# PIC32CZ8110CA90208 register map
Vendor: Microchip Technology; Series: PIC32CZCA90; File version: 0
CPU: CM7 r1p1, little endian, MPU, FPU, double-precision FPU, I-cache, D-cache, ITCM, DTCM, 3 interrupt priority bits, 222 interrupts
Registers are 32-bit, read-write, reset 0x0 unless marked. A register's access mark holds for its fields unless they carry their own. Offsets are from the block's base; [hi:lo] are bit positions; {n}, {i} and the like mark numbered series; 'fields as' and 'values as' point back to an identical list.

## PAC — Peripheral Access Controller
Base 0x44810000
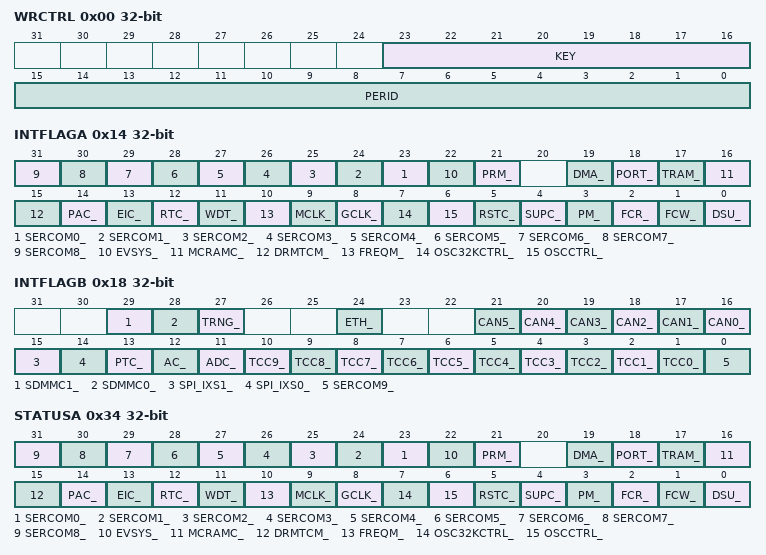
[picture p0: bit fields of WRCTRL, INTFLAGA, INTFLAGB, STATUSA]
0x00 WRCTRL — Write control
  [23:16] KEY — Peripheral access control key
    0=OFF (No action); 1=CLR (Clear protection); 2=SET (Set protection); 3=SETLCK (Set and lock protection)
  [15:0] PERID — Peripheral identifier
0x04 EVCTRL 8-bit — Event control
  [0] ERREO — Peripheral acess error event output
0x08 INTENCLR 8-bit write-1-clears — Interrupt enable clear
  [0] ERR — Peripheral access error interrupt disable
0x09 INTENSET 8-bit write-1-sets — Interrupt enable set
  [0] ERR — Peripheral access error interrupt enable
0x10 INTFLAGAHB write-1-clears — Bridge interrupt flag status
0x14 INTFLAGA write-1-clears — Peripheral interrupt flag status - Bridge A
  [n+23] SERCOM{n}_ (n=0..8), [22] EVSYS_, [21] PRM_, [19] DMA_, [18] PORT_, [17] TRAM_, [16] MCRAMC_, [15] DRMTCM_, [14] PAC_, [13] EIC_, [12] RTC_, [11] WDT_, [10] FREQM_, [9] MCLK_, [8] GCLK_, [7] OSC32KCTRL_, [6] OSCCTRL_, [5] RSTC_, [4] SUPC_, [3] PM_, [2] FCR_, [1] FCW_, [0] DSU_
0x18 INTFLAGB write-1-clears — Peripheral interrupt flag status - Bridge B
  [29] SDMMC1_, [28] SDMMC0_, [27] TRNG_, [24] ETH_, [n+16] CAN{n}_ (n=0..5), [15] SPI_IXS1_, [14] SPI_IXS0_, [13] PTC_, [12] AC_, [11] ADC_, [n+1] TCC{n}_ (n=0..9), [0] SERCOM9_
0x1C INTFLAGC write-1-clears — Peripheral interrupt flag status - Bridge C
  [2] MLB_
0x34 STATUSA ro — Peripheral write protection status - Bridge A
  [n+23] SERCOM{n}_ (n=0..8) — SERCOM{n} APB Protect Enable
  [22] EVSYS_ — EVSYS APB Protect Enable
  [21] PRM_ — PRM APB Protect Enable
  [19] DMA_ — DMA APB Protect Enable
  [18] PORT_ — PORT APB Protect Enable
  [17] TRAM_ — TRAM APB Protect Enable
  [16] MCRAMC_ — MCRAMC APB Protect Enable
  [15] DRMTCM_ — DRMTCM APB Protect Enable
  [14] PAC_ — PAC APB Protect Enable
  [13] EIC_ — EIC APB Protect Enable
  [12] RTC_ — RTC APB Protect Enable
  [11] WDT_ — WDT APB Protect Enable
  [10] FREQM_ — FREQM APB Protect Enable
  [9] MCLK_ — MCLK APB Protect Enable
  [8] GCLK_ — GCLK APB Protect Enable
  [7] OSC32KCTRL_ — OSC32KCTRL APB Protect Enable
  [6] OSCCTRL_ — OSCCTRL APB Protect Enable
  [5] RSTC_ — RSTC APB Protect Enable
  [4] SUPC_ — SUPC APB Protect Enable
  [3] PM_ — PM APB Protect Enable
  [2] FCR_ — FCR APB Protect Enable
  [1] FCW_ — FCW APB Protect Enable
  [0] DSU_ — DSU APB Protect Enable
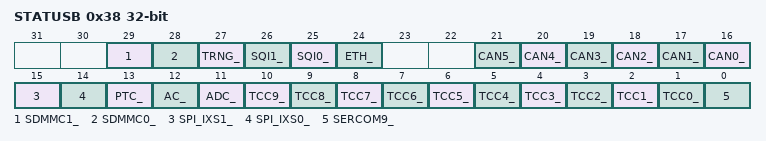
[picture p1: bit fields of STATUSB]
0x38 STATUSB ro — Peripheral write protection status - Bridge B
  [29] SDMMC1_ — SDMMC1 APB Protect Enable
  [28] SDMMC0_ — SDMMC0 APB Protect Enable
  [27] TRNG_ — TRNG APB Protect Enable
  [26] SQI1_ — SQI1 APB Protect Enable
  [25] SQI0_ — SQI0 APB Protect Enable
  [24] ETH_ — ETH APB Protect Enable
  [n+16] CAN{n}_ (n=0..5) — CAN{n} APB Protect Enable
  [15] SPI_IXS1_ — SPI_IXS1 APB Protect Enable
  [14] SPI_IXS0_ — SPI_IXS0 APB Protect Enable
  [13] PTC_ — PTC APB Protect Enable
  [12] AC_ — AC APB Protect Enable
  [11] ADC_ — ADC APB Protect Enable
  [n+1] TCC{n}_ (n=0..9) — TCC{n} APB Protect Enable
  [0] SERCOM9_ — SERCOM9 APB Protect Enable
0x3C STATUSC ro reset 0x38 — Peripheral write protection status - Bridge C
  [2] MLB_ — MLB APB Protect Enable

## PM — Power Manager
Base 0x44010000
0x00 CTRLA 8-bit — Control A
  [2] IORET — I/O Retention
    0=NOIORET (When the device exits the HIBERNATE or BACKUP mode, the I/O line configuration are released.); 1=IORET (When the device exits the HIBERNATE or BACKUP mode, the I/O line configuration are stretched.)
0x01 SLEEPCFG 8-bit reset 0x2 — Sleep Configuration
  [2:0] SLEEPMODE
    2=IDLE (CPU, AHB and APB clocks are OFF); 4=STANDBY (All Clocks are OFF); 5=HIBERNATE (Backup domain is ON as well as some PDRAMs); 6=BACKUP (Only Backup domain is powered ON); 7=OFF (All power domains are powered OFF)
0x04 INTENCLR 8-bit write-1-clears — Interrupt Enable Clear
  [0] SLEEPRDY — Backup Sleep Mode Entry Ready Enable
0x05 INTENSET 8-bit write-1-sets — Interrupt Enable Set
  [0] SLEEPRDY — Backup Sleep Mode Entry Ready Enable
0x06 INTFLAG 8-bit write-1-clears — Interrupt Flag Status and Clear
  [0] SLEEPRDY — Backup Sleep Mode Entry Ready
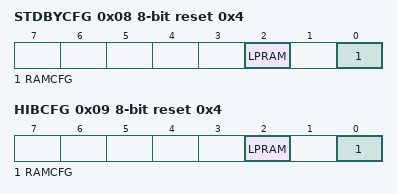
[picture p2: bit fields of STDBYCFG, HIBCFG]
0x08 STDBYCFG 8-bit reset 0x4 — Standby Configuration
  [2] LPRAM — Low Power RAM Enable
  [0] RAMCFG — Ram Configuration
    0=RET (All the RAMs are retained); 1=OFF (Only the first 32K bytes are retained)
0x09 HIBCFG 8-bit reset 0x4 — Hibernate Configuration
  fields as STDBYCFG

## Notices in the file
Copyright (c) 2026 Microchip Technology Inc.
SPDX-License-Identifier: Apache-2.0
Licensed under the Apache License, Version 2.0 (the "License");
you may not use this file except in compliance with the License.
You may obtain a copy of the License at
http://www.apache.org/licenses/LICENSE-2.0
Unless required by applicable law or agreed to in writing, software
distributed under the License is distributed on an "AS IS" BASIS,
WITHOUT WARRANTIES OR CONDITIONS OF ANY KIND, either express or implied.
See the License for the specific language governing permissions and
limitations under the License.
